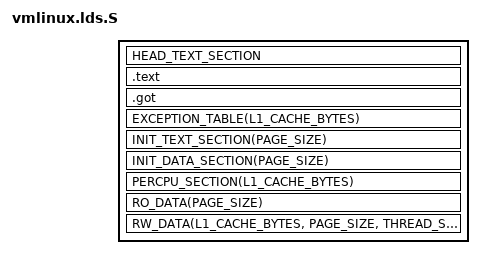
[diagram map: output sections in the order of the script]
FASTVC-BENCH-CORPUS:linux-main-100k-v1-e0bd41dc-8e12-4f1b-978d-a3645ae59da0
/* SPDX-License-Identifier: GPL-2.0-or-later */
/*
 * Copyright (C) 2009 Thomas Chou <thomas@wytron.com.tw>
 */
#include <asm/page.h>
/* bench 5809.2.0 ee01f3018373 */
/* bench 5809.2.1 ca152e21d006 */
/* bench 5809.2.2 4b8c9e67109b */
/* bench 5809.2.3 a9cedd88ecce */
/* bench 5809.2.4 0dd185125182 */
/* bench 5809.2.5 d036c439ee68 */
/* bench 5809.2.6 0577587ffc7c */

OUTPUT_FORMAT("elf32-littlenios2", "elf32-littlenios2", "elf32-littlenios2")

OUTPUT_ARCH(nios)
ENTRY(_start)	/* Defined in head.S */

jiffies = jiffies_64;

SECTIONS
{
	. = CONFIG_NIOS2_MEM_BASE | CONFIG_NIOS2_KERNEL_REGION_BASE;
/* bench 23175.3.0 ad2169c65815 */
/* bench 23175.3.1 96b10b4d2787 */
/* bench 23175.3.2 b835a52be80c */
/* bench 23175.3.3 7ddad7494381 */
/* bench 23175.3.4 475d5af6da20 */
/* bench 23175.3.5 4dcdf84bd49c */
/* bench 23175.3.6 535451fc33a8 */
/* bench 23175.3.7 e1b95c6a2173 */
/* bench 23175.3.8 4bddb3805fea */
/* bench 23175.3.9 cb4c272a0fcc */
/* bench 23175.3.10 b791ee242b5b */
/* bench 23175.3.11 aef3e728d43f */
/* bench 23175.3.12 bd3ddf3593a2 */

	_text = .;
	_stext = .;
	HEAD_TEXT_SECTION
	.text : {
		TEXT_TEXT
		SCHED_TEXT
		CPUIDLE_TEXT
		LOCK_TEXT
		IRQENTRY_TEXT
		SOFTIRQENTRY_TEXT
		KPROBES_TEXT
	} =0
	_etext = .;

	.got : {
		*(.got.plt)
		*(.igot.plt)
		*(.got)
		*(.igot)
	}

	EXCEPTION_TABLE(L1_CACHE_BYTES)

	. = ALIGN(PAGE_SIZE);
	__init_begin = .;
	INIT_TEXT_SECTION(PAGE_SIZE)
	INIT_DATA_SECTION(PAGE_SIZE)
	PERCPU_SECTION(L1_CACHE_BYTES)
	__init_end = .;

	_sdata = .;
	RO_DATA(PAGE_SIZE)
	RW_DATA(L1_CACHE_BYTES, PAGE_SIZE, THREAD_SIZE)
	_edata = .;
/* bench 18502.1.0 1fb929f0111e */
/* bench 18502.1.1 0b28def470e4 */
/* bench 18502.1.2 63a4a554cefa */
/* bench 18502.1.3 bd40a2fad0c7 */
/* bench 18502.1.4 ea8e1f5da3d9 */
/* bench 18502.1.5 53de7e459c55 */
	_end = .;

	STABS_DEBUG
	DWARF_DEBUG
	ELF_DETAILS

	DISCARDS
}
